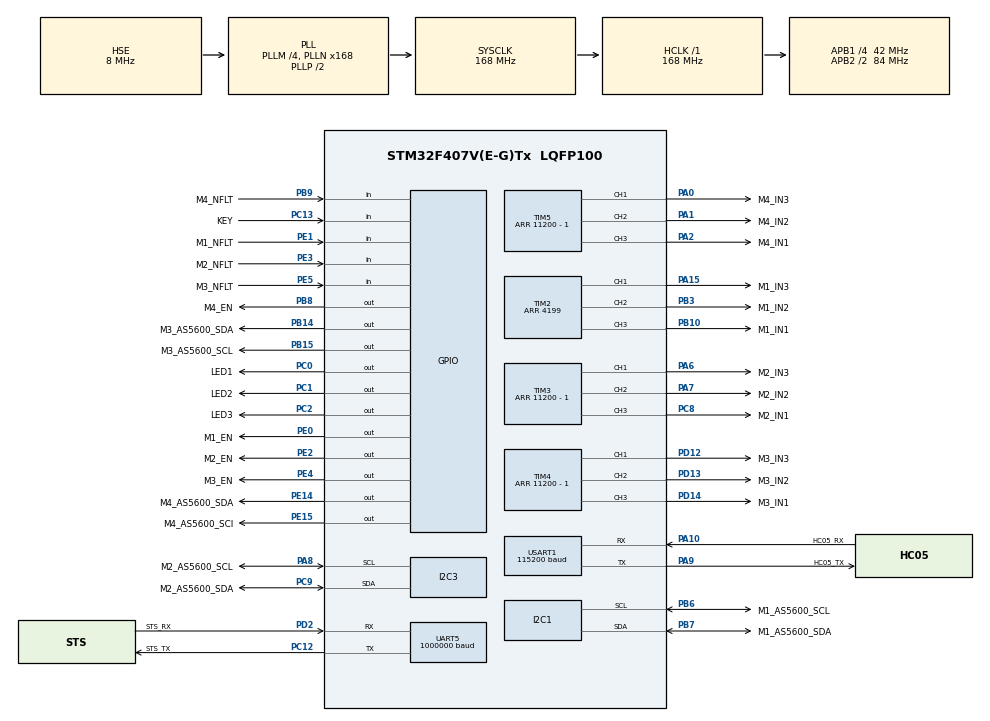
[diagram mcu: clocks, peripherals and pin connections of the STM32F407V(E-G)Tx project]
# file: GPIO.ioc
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I2C1.I2C_Mode=I2C_Fast
I2C3.I2C_Mode=I2C_Fast
Mcu.Family=STM32F4
Mcu.Name=STM32F407V(E-G)Tx
Mcu.Package=LQFP100
NVIC.PriorityGroup=NVIC_PRIORITYGROUP_4
NVIC.TIM6_DAC_IRQn=true\:0\:0\:false\:false\:true\:true\:true\:true
NVIC.TIM7_IRQn=true\:0\:0\:false\:false\:true\:true\:true\:true
NVIC.UART5_IRQn=true\:0\:0\:false\:false\:true\:true\:true\:true
NVIC.USART1_IRQn=true\:0\:0\:false\:false\:true\:true\:true\:true
PA0-WKUP.GPIO_Label=M4_IN3
PA0-WKUP.Signal=S_TIM5_CH1
PA1.GPIO_Label=M4_IN2
PA1.Signal=S_TIM5_CH2
PA10.GPIO_Label=HC05_RX
PA10.Mode=Asynchronous
PA10.Signal=USART1_RX
PA15.GPIO_Label=M1_IN3
PA15.Signal=S_TIM2_CH1_ETR
PA2.GPIO_Label=M4_IN1
PA2.Signal=S_TIM5_CH3
PA6.GPIO_Label=M2_IN3
PA6.Signal=S_TIM3_CH1
PA7.GPIO_Label=M2_IN2
PA7.Signal=S_TIM3_CH2
PA8.GPIO_Label=M2_AS5600_SCL
PA8.Mode=I2C
PA8.Signal=I2C3_SCL
PA9.GPIO_Label=HC05_TX
PA9.Mode=Asynchronous
PA9.Signal=USART1_TX
PB10.GPIO_Label=M1_IN1
PB10.Signal=S_TIM2_CH3
PB14.GPIO_Label=M3_AS5600_SDA
PB14.GPIO_PuPd=GPIO_NOPULL
PB14.GPIO_Speed=GPIO_SPEED_FREQ_HIGH
PB14.Signal=GPIO_Output
PB15.GPIO_Label=M3_AS5600_SCL
PB15.GPIO_PuPd=GPIO_NOPULL
PB15.GPIO_Speed=GPIO_SPEED_FREQ_HIGH
PB15.Signal=GPIO_Output
PB3.GPIO_Label=M1_IN2
PB3.Signal=S_TIM2_CH2
PB6.GPIO_Label=M1_AS5600_SCL
PB6.GPIO_Pu=GPIO_NOPULL
PB6.Mode=I2C
PB6.Signal=I2C1_SCL
PB7.GPIO_Label=M1_AS5600_SDA
PB7.Mode=I2C
PB7.Signal=I2C1_SDA
PB8.GPIO_Label=M4_EN
PB8.GPIO_PuPd=GPIO_PULLDOWN
PB8.PinState=GPIO_PIN_RESET
PB8.Signal=GPIO_Output
PB9.GPIO_Label=M4_NFLT
PB9.Signal=GPIO_Input
PC0.GPIO_Label=LED1
PC0.PinState=GPIO_PIN_SET
PC0.Signal=GPIO_Output
PC1.GPIO_Label=LED2
PC1.PinState=GPIO_PIN_SET
PC1.Signal=GPIO_Output
PC12.GPIO_Label=STS_TX
PC12.Mode=Asynchronous
PC12.Signal=UART5_TX
PC13-ANTI_TAMP.GPIO_Label=KEY
PC13-ANTI_TAMP.GPIO_Mode=GPIO_MODE_INPUT
PC13-ANTI_TAMP.GPIO_PuPd=GPIO_PULLDOWN
PC13-ANTI_TAMP.Signal=GPIO_Input
PC2.GPIO_Label=LED3
PC2.PinState=GPIO_PIN_SET
PC2.Signal=GPIO_Output
PC8.GPIO_Label=M2_IN1
PC8.Signal=S_TIM3_CH3
PC9.GPIO_Label=M2_AS5600_SDA
PC9.Mode=I2C
PC9.Signal=I2C3_SDA
PD12.GPIO_Label=M3_IN3
PD12.Signal=S_TIM4_CH1
PD13.GPIO_Label=M3_IN2
PD13.Signal=S_TIM4_CH2
PD14.GPIO_Label=M3_IN1
PD14.Signal=S_TIM4_CH3
PD2.GPIO_Label=STS_RX
PD2.Mode=Asynchronous
PD2.Signal=UART5_RX
PE0.GPIO_Label=M1_EN
PE0.GPIO_PuPd=GPIO_PULLDOWN
PE0.PinState=GPIO_PIN_RESET
PE0.Signal=GPIO_Output
PE1.GPIO_Label=M1_NFLT
PE1.Signal=GPIO_Input
PE14.GPIO_Label=M4_AS5600_SDA
PE14.GPIO_PuPd=GPIO_NOPULL
PE14.GPIO_Speed=GPIO_SPEED_FREQ_HIGH
PE14.Signal=GPIO_Output
PE15.GPIO_Label=M4_AS5600_SCl
PE15.GPIO_PuPd=GPIO_NOPULL
PE15.GPIO_Speed=GPIO_SPEED_FREQ_HIGH
PE15.Signal=GPIO_Output
PE2.GPIO_Label=M2_EN
PE2.GPIO_PuPd=GPIO_PULLDOWN
PE2.PinState=GPIO_PIN_RESET
PE2.Signal=GPIO_Output
PE3.GPIO_Label=M2_NFLT
PE3.Signal=GPIO_Input
PE4.GPIO_Label=M3_EN
PE4.GPIO_PuPd=GPIO_PULLDOWN
PE4.PinState=GPIO_PIN_RESET
PE4.Signal=GPIO_Output
PE5.GPIO_Label=M3_NFLT
PE5.Signal=GPIO_Input
PH0-OSC_IN.Mode=HSE-External-Oscillator
PH0-OSC_IN.Signal=RCC_OSC_IN
PH1-OSC_OUT.Mode=HSE-External-Oscillator
PH1-OSC_OUT.Signal=RCC_OSC_OUT
ProjectManager.HeapSize=0x200
ProjectManager.StackSize=0x400
ProjectManager.TargetToolchain=MDK-ARM V5.32
RCC.48MHZClocksFreq_Value=84000000
RCC.AHBFreq_Value=168000000
RCC.APB1CLKDivider=RCC_HCLK_DIV4
RCC.APB1Freq_Value=42000000
RCC.APB1TimFreq_Value=84000000
RCC.APB2CLKDivider=RCC_HCLK_DIV2
RCC.APB2Freq_Value=84000000
RCC.APB2TimFreq_Value=168000000
RCC.CortexFreq_Value=168000000
RCC.HCLKFreq_Value=168000000
RCC.HSE_VALUE=8000000
RCC.HSI_VALUE=16000000
RCC.LSE_VALUE=32768
RCC.PLLM=4
RCC.PLLN=168
RCC.PLLSourceVirtual=RCC_PLLSOURCE_HSE
RCC.SYSCLKFreq_VALUE=168000000
RCC.SYSCLKSource=RCC_SYSCLKSOURCE_PLLCLK
RCC.VCOOutputFreq_Value=336000000
SH.S_TIM2_CH1_ETR.0=TIM2_CH1,PWM Generation1 CH1
SH.S_TIM2_CH2.0=TIM2_CH2,PWM Generation2 CH2
SH.S_TIM2_CH3.0=TIM2_CH3,PWM Generation3 CH3
SH.S_TIM3_CH1.0=TIM3_CH1,PWM Generation1 CH1
SH.S_TIM3_CH2.0=TIM3_CH2,PWM Generation2 CH2
SH.S_TIM3_CH3.0=TIM3_CH3,PWM Generation3 CH3
SH.S_TIM4_CH1.0=TIM4_CH1,PWM Generation1 CH1
SH.S_TIM4_CH2.0=TIM4_CH2,PWM Generation2 CH2
SH.S_TIM4_CH3.0=TIM4_CH3,PWM Generation3 CH3
SH.S_TIM5_CH1.0=TIM5_CH1,PWM Generation1 CH1
SH.S_TIM5_CH2.0=TIM5_CH2,PWM Generation2 CH2
SH.S_TIM5_CH3.0=TIM5_CH3,PWM Generation3 CH3
TIM2.AutoReloadPreload=TIM_AUTORELOAD_PRELOAD_DISABLE
TIM2.Channel-PWM\ Generation1\ CH1=TIM_CHANNEL_1
TIM2.Channel-PWM\ Generation2\ CH2=TIM_CHANNEL_2
TIM2.Channel-PWM\ Generation3\ CH3=TIM_CHANNEL_3
TIM2.Period=4199
TIM3.Channel-PWM\ Generation1\ CH1=TIM_CHANNEL_1
TIM3.Channel-PWM\ Generation2\ CH2=TIM_CHANNEL_2
TIM3.Channel-PWM\ Generation3\ CH3=TIM_CHANNEL_3
TIM3.Period=11200 - 1
TIM4.Channel-PWM\ Generation1\ CH1=TIM_CHANNEL_1
TIM4.Channel-PWM\ Generation2\ CH2=TIM_CHANNEL_2
TIM4.Channel-PWM\ Generation3\ CH3=TIM_CHANNEL_3
TIM4.Period=11200 - 1
TIM5.Channel-PWM\ Generation1\ CH1=TIM_CHANNEL_1
TIM5.Channel-PWM\ Generation2\ CH2=TIM_CHANNEL_2
TIM5.Channel-PWM\ Generation3\ CH3=TIM_CHANNEL_3
TIM5.Period=11200 - 1
TIM6.Period=999
TIM6.Prescaler=83
TIM7.Period=49
TIM7.Prescaler=16799
UART5.BaudRate=1000000
UART5.VirtualMode=Asynchronous
USART1.BaudRate=115200
USART1.VirtualMode=VM_ASYNC
VP_TIM6_VS_ClockSourceINT.Mode=Enable_Timer
VP_TIM7_VS_ClockSourceINT.Mode=Enable_Timer
board=custom

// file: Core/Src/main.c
/* USER CODE BEGIN Header */
/**
  ******************************************************************************
  * @file           : main.c
  * @brief          : Main program body
  ******************************************************************************
  * @attention
  *
  * Copyright (c) 2024 STMicroelectronics.
  * All rights reserved.
  *
  ******************************************************************************
  */
/* USER CODE END Header */
#include "main.h"
#include "i2c.h"
#include "tim.h"
#include "usart.h"
#include "gpio.h"

/* USER CODE BEGIN Includes */
#include "foc.h"
#include "AS5600.h"
#include "col.h"
#include "led.h"
/* USER CODE END Includes */

void SystemClock_Config(void);

int main(void)
{

  /* MCU Configuration--------------------------------------------------------*/

  /* Reset of all peripherals, Initializes the Flash interface and the Systick. */
  HAL_Init();

  /* Configure the system clock */
  SystemClock_Config();

  /* Initialize all configured peripherals */
  MX_GPIO_Init();
  MX_USART1_UART_Init();
  MX_I2C1_Init();
  MX_I2C3_Init();
  MX_TIM2_Init();
  MX_TIM3_Init();
  MX_TIM4_Init();
  MX_TIM5_Init();
  MX_UART5_Init();
  MX_TIM6_Init();
  MX_TIM7_Init();
  /* USER CODE BEGIN 2 */
  Encoder_Init(0U);
  HAL_TIM_Base_Start_IT(&htim6);
  col_init();

  /* Uncomment to run a one-shot ID-mapping test (prints over USART1).
     col_test_servo_map();
     col_test_motor_map();
  */
  /* USER CODE END 2 */

  /* Infinite loop */
  /* USER CODE BEGIN WHILE */
    while (1)
    {
        col_update(HAL_GetTick());
    /* USER CODE END WHILE */

    }
}

void SystemClock_Config(void)
{
  RCC_OscInitTypeDef RCC_OscInitStruct = {0};
  RCC_ClkInitTypeDef RCC_ClkInitStruct = {0};

  /** Configure the main internal regulator output voltage
  */
  __HAL_RCC_PWR_CLK_ENABLE();
  __HAL_PWR_VOLTAGESCALING_CONFIG(PWR_REGULATOR_VOLTAGE_SCALE1);

  /** Initializes the RCC Oscillators according to the specified parameters
  * in the RCC_OscInitTypeDef structure.
  */
  RCC_OscInitStruct.OscillatorType = RCC_OSCILLATORTYPE_HSE;
  RCC_OscInitStruct.HSEState = RCC_HSE_ON;
  RCC_OscInitStruct.PLL.PLLState = RCC_PLL_ON;
  RCC_OscInitStruct.PLL.PLLSource = RCC_PLLSOURCE_HSE;
  RCC_OscInitStruct.PLL.PLLM = 4;
  RCC_OscInitStruct.PLL.PLLN = 168;
  RCC_OscInitStruct.PLL.PLLP = RCC_PLLP_DIV2;
  RCC_OscInitStruct.PLL.PLLQ = 4;
  if (HAL_RCC_OscConfig(&RCC_OscInitStruct) != HAL_OK)
  {
    Error_Handler();
  }

  /** Initializes the CPU, AHB and APB buses clocks
  */
  RCC_ClkInitStruct.ClockType = RCC_CLOCKTYPE_HCLK|RCC_CLOCKTYPE_SYSCLK
                              |RCC_CLOCKTYPE_PCLK1|RCC_CLOCKTYPE_PCLK2;
  RCC_ClkInitStruct.SYSCLKSource = RCC_SYSCLKSOURCE_PLLCLK;
  RCC_ClkInitStruct.AHBCLKDivider = RCC_SYSCLK_DIV1;
  RCC_ClkInitStruct.APB1CLKDivider = RCC_HCLK_DIV4;
  RCC_ClkInitStruct.APB2CLKDivider = RCC_HCLK_DIV2;

  if (HAL_RCC_ClockConfig(&RCC_ClkInitStruct, FLASH_LATENCY_5) != HAL_OK)
  {
    Error_Handler();
  }
}

void Error_Handler(void)
{
  __disable_irq();
  while (1)
  {
  }
}
